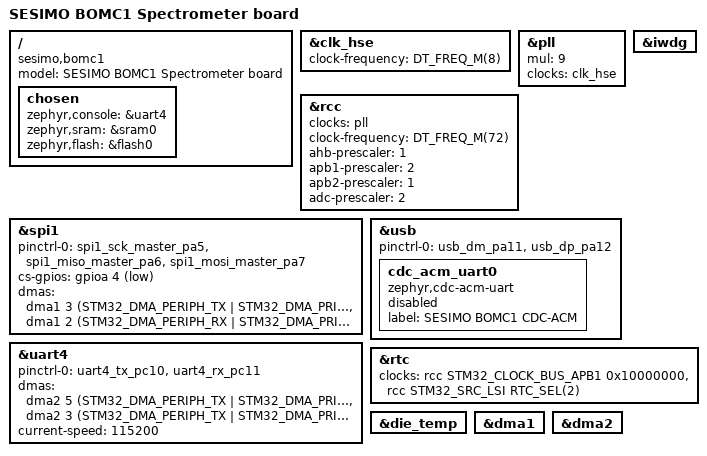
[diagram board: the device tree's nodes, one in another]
/*
 * Copyright (c) 2017 Linaro Limited
 *
 * SPDX-License-Identifier: Apache-2.0
 */

/dts-v1/;
#include <st/f1/stm32f103Xc.dtsi>
#include <st/f1/stm32f103r(c-d-e)tx-pinctrl.dtsi>
#include <zephyr/dt-bindings/input/input-event-codes.h>

/ {
	model = "SESIMO BOMC1 Spectrometer board";
	compatible = "sesimo,bomc1";

	chosen {
        zephyr,console = &uart4;
		zephyr,sram = &sram0;
		zephyr,flash = &flash0;
	};
};

&clk_hse {
	clock-frequency = <DT_FREQ_M(8)>; /* 8MHz crystal */
	status = "okay";
};

&pll {
	mul = <9>;
	clocks = <&clk_hse>;
	status = "okay";
};

&rcc {
	clocks = <&pll>;
	clock-frequency = <DT_FREQ_M(72)>;
	ahb-prescaler = <1>;
	apb1-prescaler = <2>;
	apb2-prescaler = <1>;
	adc-prescaler = <2>;
};

&spi1 {
	pinctrl-0 = <&spi1_sck_master_pa5 &spi1_miso_master_pa6 &spi1_mosi_master_pa7>;
	pinctrl-names = "default";
	cs-gpios = <&gpioa 4 (GPIO_ACTIVE_LOW | GPIO_PULL_UP)>;
	status = "okay";
    dmas = <&dma1 3 (STM32_DMA_PERIPH_TX | STM32_DMA_PRIORITY_HIGH)>,
           <&dma1 2 (STM32_DMA_PERIPH_RX | STM32_DMA_PRIORITY_HIGH)>;
    dma-names = "tx", "rx";
};

&uart4 {
    status = "okay";
    pinctrl-0 = <&uart4_tx_pc10 &uart4_rx_pc11>;
    pinctrl-names = "default";
    dmas = <&dma2 5 (STM32_DMA_PERIPH_TX | STM32_DMA_PRIORITY_HIGH)
            &dma2 3 (STM32_DMA_PERIPH_TX | STM32_DMA_PRIORITY_HIGH)>;
    dma-names = "tx", "rx";
    current-speed = <115200>;
};

zephyr_udc0: &usb {
    pinctrl-0 = <&usb_dm_pa11 &usb_dp_pa12>;
    pinctrl-names = "default";
    status = "okay";

    cdc_acm_uart0: cdc_acm_uart0 {
        compatible = "zephyr,cdc-acm-uart";
        label = "SESIMO BOMC1 CDC-ACM";
        status = "disabled";
    };
};

&iwdg {
	status = "okay";
};

&rtc {
	clocks = <&rcc STM32_CLOCK_BUS_APB1 0x10000000>,
		 <&rcc STM32_SRC_LSI RTC_SEL(2)>;
	status = "okay";
};

&die_temp {
	status = "okay";
};

&dma1 {
	status = "okay";
};

&dma2 {
    status = "okay";
};
